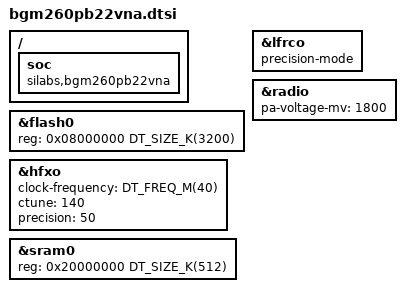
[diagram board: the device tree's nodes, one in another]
/*
 * Copyright (c) 2025 Silicon Laboratories Inc.
 *
 * SPDX-License-Identifier: Apache-2.0
 */

#include <mem.h>
#include <silabs/xg26/bgm26.dtsi>

/ {
	soc {
		compatible = "silabs,bgm260pb22vna", "silabs,bgm26", "silabs,xg26", "silabs,efr32",
			     "simple-bus";
	};
};

&flash0 {
	reg = <0x08000000 DT_SIZE_K(3200)>;
};

&hfxo {
	clock-frequency = <DT_FREQ_M(40)>;
	ctune = <140>;
	precision = <50>;
	status = "okay";
};

&lfrco {
	precision-mode;
};

&radio {
	pa-voltage-mv = <1800>;
};

&sram0 {
	reg = <0x20000000 DT_SIZE_K(512)>;
};
